# STM32MP21_CA35 register map
File version: 0.4
CPU: CM33 r0p1, little endian, MPU, FPU, vendor SysTick, 8 interrupt priority bits
Registers are 32-bit, read-write, reset 0x0 unless marked. A register's access mark holds for its fields unless they carry their own. Offsets are from the block's base; [hi:lo] are bit positions; lines under a group give offsets from that group; {n}, {i} and the like mark numbered series; 'fields as' and 'values as' point back to an identical list.

## GICV — GICV address block description
Base 0x4AC60000
Same registers: GICV_S 0x5AC60000
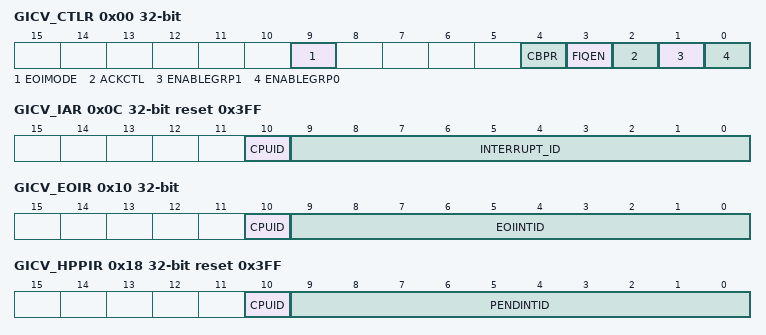
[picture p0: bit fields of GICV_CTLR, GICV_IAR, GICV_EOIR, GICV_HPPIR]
0x00 GICV_CTLR — GICV virtual machine control register
  [9] EOIMODE — End of interrupt mode
  [4] CBPR — BPR control
  [3] FIQEN — FIQ enable for group 0 interrupts
  [2] ACKCTL — Acknowledge control
  [1] ENABLEGRP1 — This bit enables the signaling of group 1 virtual interrupts by the GICV to the virtual machine.
  [0] ENABLEGRP0 — This bit enables the signaling of group 0 virtual interrupts by the GICV to the virtual machine.
0x04 GICV_PMR — GICV VM priority mask register
  [7:3] PRIORITY — Priority mask level for the virtual CPU interface
0x08 GICV_BPR reset 0x2 — GICV VM binary point register
  [2:0] BINARY_POINT — This bit field value controls how the 8-bit virtual interrupt priority field is split into a group priority field, used to determine virtual interrupt preemption, and a subpriority field.
0x0C GICV_IAR ro reset 0x3FF — GICV VM interrupt acknowledge register
  [10] CPUID — If HW is cleared to 0 in GICH_LRx (indicating that the interrupt is triggered in software), the value of CPUID in GICH_LRx, that indicates the CPU ID, is returned in this bit.
  [9:0] INTERRUPT_ID
0x10 GICV_EOIR wo reset not defined — GICV VM end of interrupt register
  [10] CPUID — On a multiprocessor implementation, if the write refers to an SGI, this bit contains the CPUID value from the corresponding GICV_IAR access.
  [9:0] EOIINTID — If HW is set to 1 in GICH_LRx (indicating a hardware interrupt), a deactivate request is sent to the physical distributor, identifying the physical ID from the corresponding bit field
0x14 GICV_RPR ro reset 0xFF — GICV VM running priority register
  [7:3] PRIORITY — Current running priority on the virtual CPU interface
0x18 GICV_HPPIR ro reset 0x3FF — GICV VM highest priority pending interrupt register
  [10] CPUID — On a multiprocessor implementation, if GICH_LRx.
  [9:0] PENDINTID — The virtual interrupt ID of the highest-priority pending virtual interrupt
0x1C GICV_ABPR reset 0x3 — GICV VM aliased binary point register
  fields as GICV_BPR
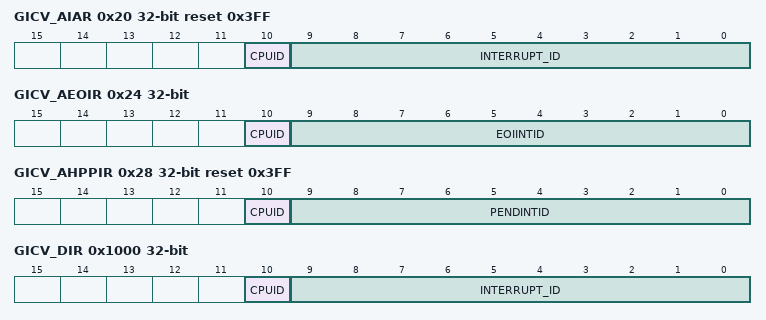
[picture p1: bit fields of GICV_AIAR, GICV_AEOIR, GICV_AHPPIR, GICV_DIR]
0x20 GICV_AIAR ro reset 0x3FF — GICV VM aliased interrupt register
  [10] CPUID — If HW is cleared to 0 in GICH_LRx (indicating that the interrupt is triggered in software),
  [9:0] INTERRUPT_ID
0x24 GICV_AEOIR wo reset not defined — GICV VM aliased end of interrupt register
  [10] CPUID — On a multiprocessor implementation, if the write refers to an SGI, this field contains the CPUID value from the corresponding GICV_IAR access.
  [9:0] EOIINTID — If HW is set to 1 in GICH_LRx (indicating an hardware interrupt), a deactivate request is sent to the physical distributor, identifying the physical ID from the corresponding field
0x28 GICV_AHPPIR ro reset 0x3FF — GICV VM aliased highest priority pending interrupt register
  [10] CPUID — If HW is set to 1 in GICH_LRx (indicating an hardware interrupt), a deactivate request is sent to the physical distributor, identifying the physical ID from the corresponding field
  [9:0] PENDINTID — This bit field contains the virtual interrupt ID of the highest-priority pending virtual interrupt, if that virtual interrupt is a group 1 virtual interrupt.
0xD0 GICV_APR0 — GICV VM active priority register
  [31:0] APR0 — Active priority
0xFC GICV_IIDR ro reset 0x202143B — GICV VM CPU interface identification register
  [31:0] IIDR — see GICC_IIDR description
0x1000 GICV_DIR wo reset not defined — GICV VM deactivate interrupt register
  [10] CPUID — This bit identifies the processor core that requested the interrupt.
  [9:0] INTERRUPT_ID

## HDP — HDP address block description
Base 0x44090000
Same registers: HDP_S 0x54090000
0x00 HDP_CTRL — HDP control register
  [0] EN — HDP enable (valid if enabled in BSEC)
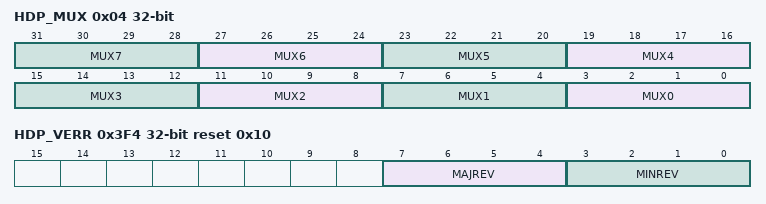
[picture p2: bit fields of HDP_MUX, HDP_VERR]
0x04 HDP_MUX — HDP multiplexer control register
  [4n+3:4n] MUX{n} (n=0..7) — Selection of the HDPy output among the 16 available signals
0x10 HDP_VAL ro — HDP read back value register
  [7:0] HDPVAL — Value of the HDP signals
0x14 HDP_GPOSET wo — HDP general purpose output set register
  [7:0] HDPGPOSET — When a bit is written to 1, the corresponding HDP GPO is set.
0x18 HDP_GPOCLR wo — HDP general purpose output clear register
  [7:0] HDPGPOCLR — When a bit is written to 1, the corresponding HDP GPO is cleared.
0x1C HDP_GPOVAL — HDP general purpose output value register
  [7:0] HDPGPOVAL — When written, this bit field defines the value of the HDP GPO.
0x3F4 HDP_VERR ro reset 0x10 — HDP version register
  [7:4] MAJREV — HDP major revision
  [3:0] MINREV — HDP minor revision
0x3F8 HDP_IPIDR ro reset 0x30002 — HDP identification register
  [31:0] ID — HDP identifier
0x3FC HDP_SIDR ro reset 0xA3C5DD01 — HDP size identification register
  [31:0] SID — Size identifier
